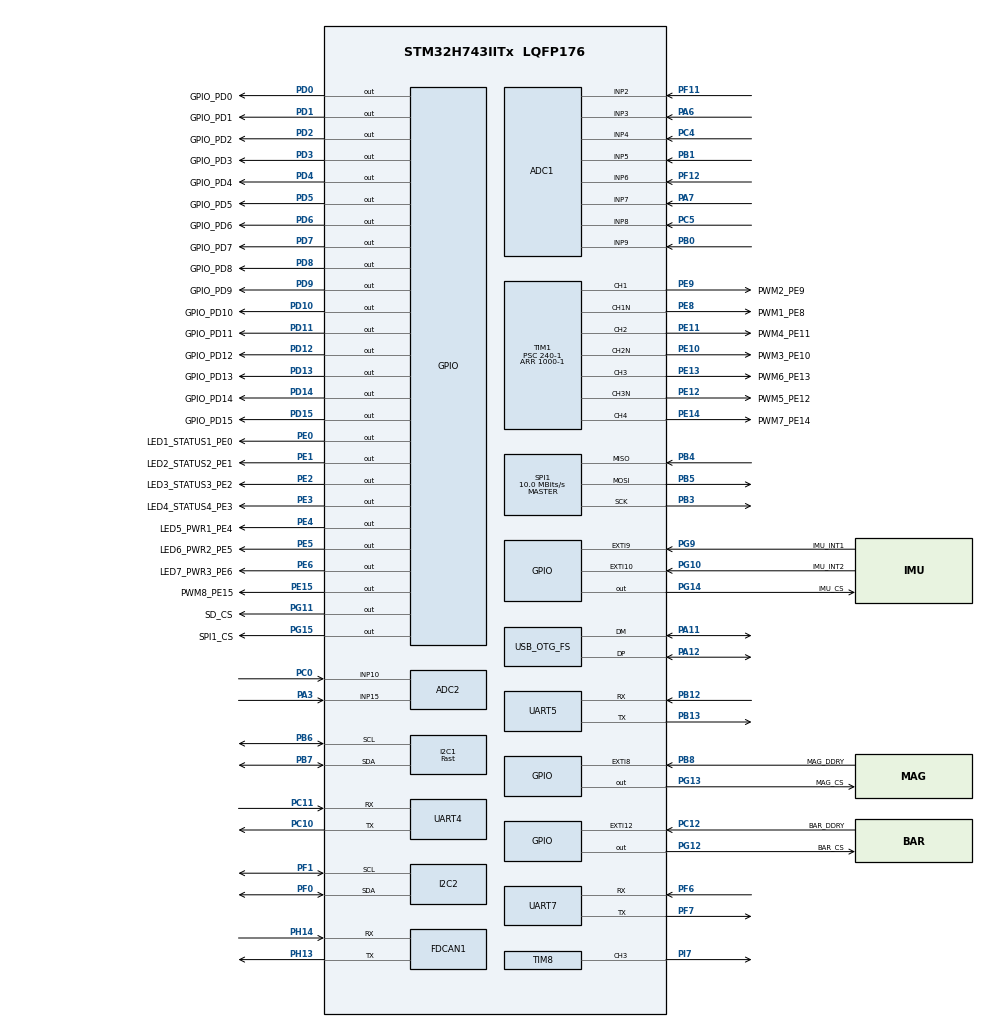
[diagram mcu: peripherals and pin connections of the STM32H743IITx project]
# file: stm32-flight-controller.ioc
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ADC1.Channel-1\#ChannelRegularConversion=ADC_CHANNEL_6
ADC1.ClockPrescaler=ADC_CLOCK_ASYNC_DIV2
ADC1.NbrOfConversionFlag=1
ADC1.OffsetNumber-1\#ChannelRegularConversion=ADC_OFFSET_NONE
ADC1.OffsetSignedSaturation-1\#ChannelRegularConversion=DISABLE
ADC1.Rank-1\#ChannelRegularConversion=1
ADC1.SamplingTime-1\#ChannelRegularConversion=ADC_SAMPLETIME_1CYCLE_5
ADC1.master=1
ADC2.Channel-0\#ChannelRegularConversion=ADC_CHANNEL_10
ADC2.ClockPrescaler=ADC_CLOCK_ASYNC_DIV2
ADC2.NbrOfConversionFlag=1
ADC2.OffsetNumber-0\#ChannelRegularConversion=ADC_OFFSET_NONE
ADC2.OffsetSignedSaturation-0\#ChannelRegularConversion=DISABLE
ADC2.Rank-0\#ChannelRegularConversion=1
ADC2.SamplingTime-0\#ChannelRegularConversion=ADC_SAMPLETIME_1CYCLE_5
CORTEX_M7.default_mode_Activation=1
FDCAN1.CalculateBaudRateNominal=1499999
FDCAN1.CalculateTimeBitNominal=666
FDCAN1.CalculateTimeQuantumNominal=133.33333333333334
FREERTOS.Mutexes01=spi1Mutex,Dynamic,NULL,Available;i2c1Mutex,Dynamic,NULL,Available;i2c2Mutex,Dynamic,NULL,Available;usbMutex,Dynamic,NULL,Available;fdcanMutex,Dynamic,NULL,Available
FREERTOS.Tasks01=defaultTask,24,512,StartDefaultTask,Default,NULL,Dynamic,NULL,NULL;statusLedTask,8,128,StartStatusLedTask,As external,NULL,Dynamic,NULL,NULL;gpsTask,24,512,StartGpsTask,As external,NULL,Dynamic,NULL,NULL;imuTask,24,512,StartImuTask,As external,NULL,Dynamic,NULL,NULL;magTask,24,512,StartMagTask,As external,NULL,Dynamic,NULL,NULL;barTask,24,512,StartBarTask,As external,NULL,Dynamic,NULL,NULL;fusionTask,40,1024,StartFusionTask,As external,NULL,Dynamic,NULL,NULL;controlTask,48,1024,StartControlTask,As external,NULL,Dynamic,NULL,NULL;tofTask,24,512,StartTofTask,As external,NULL,Dynamic,NULL,NULL
FREERTOS.configENABLE_FPU=1
FREERTOS.configTOTAL_HEAP_SIZE=51200
FREERTOS.configUSE_NEWLIB_REENTRANT=0
I2C1.I2C_Speed_Mode=I2C_Fast
I2C1.Timing=0x00B03FDB
I2C2.Timing=0x307075B1
Mcu.Family=STM32H7
Mcu.Name=STM32H743IITx
Mcu.Package=LQFP176
NVIC.OTG_FS_IRQn=true\:5\:0\:false\:false\:true\:true\:false\:true\:true
NVIC.PriorityGroup=NVIC_PRIORITYGROUP_4
NVIC.TIM2_IRQn=true\:15\:0\:false\:false\:true\:false\:false\:true\:true
NVIC.TimeBase=TIM2_IRQn
NVIC.TimeBaseIP=TIM2
NVIC.UART4_IRQn=true\:5\:0\:false\:false\:true\:true\:true\:true\:true
PA11.Mode=Device_Only
PA11.Signal=USB_OTG_FS_DM
PA12.Mode=Device_Only
PA12.Signal=USB_OTG_FS_DP
PA13\ (JTMS/SWDIO).Mode=Serial_Wire
PA13\ (JTMS/SWDIO).Signal=DEBUG_JTMS-SWDIO
PA14\ (JTCK/SWCLK).Mode=Serial_Wire
PA14\ (JTCK/SWCLK).Signal=DEBUG_JTCK-SWCLK
PA3.Signal=ADCx_INP15
PA6.Signal=ADCx_INP3
PA7.Signal=ADCx_INP7
PB0.Signal=ADCx_INP9
PB1.Signal=ADCx_INP5
PB12.Mode=Asynchronous
PB12.Signal=UART5_RX
PB13.Mode=Asynchronous
PB13.Signal=UART5_TX
PB3\ (JTDO/TRACESWO).GPIO_PuPd=GPIO_NOPULL
PB3\ (JTDO/TRACESWO).GPIO_Speed=GPIO_SPEED_FREQ_VERY_HIGH
PB3\ (JTDO/TRACESWO).Mode=Full_Duplex_Master
PB3\ (JTDO/TRACESWO).Signal=SPI1_SCK
PB4\ (NJTRST).GPIO_PuPd=GPIO_NOPULL
PB4\ (NJTRST).GPIO_Speed=GPIO_SPEED_FREQ_VERY_HIGH
PB4\ (NJTRST).Mode=Full_Duplex_Master
PB4\ (NJTRST).Signal=SPI1_MISO
PB5.GPIO_PuPd=GPIO_NOPULL
PB5.GPIO_Speed=GPIO_SPEED_FREQ_VERY_HIGH
PB5.Mode=Full_Duplex_Master
PB5.Signal=SPI1_MOSI
PB6.GPIO_Speed=GPIO_SPEED_FREQ_VERY_HIGH
PB6.Mode=I2C
PB6.Signal=I2C1_SCL
PB7.GPIO_Speed=GPIO_SPEED_FREQ_VERY_HIGH
PB7.Mode=I2C
PB7.Signal=I2C1_SDA
PB8.GPIO_Label=MAG_DDRY
PB8.Signal=GPXTI8
PC0.Signal=ADCx_INP10
PC10.Mode=Asynchronous
PC10.Signal=UART4_TX
PC11.Mode=Asynchronous
PC11.Signal=UART4_RX
PC12.GPIO_Label=BAR_DDRY
PC12.Signal=GPXTI12
PC4.Signal=ADCx_INP4
PC5.Signal=ADCx_INP8
PD0.GPIO_Label=GPIO_PD0
PD0.Signal=GPIO_Output
PD1.GPIO_Label=GPIO_PD1
PD1.Signal=GPIO_Output
PD10.GPIO_Label=GPIO_PD10
PD10.Signal=GPIO_Output
PD11.GPIO_Label=GPIO_PD11
PD11.Signal=GPIO_Output
PD12.GPIO_Label=GPIO_PD12
PD12.Signal=GPIO_Output
PD13.GPIO_Label=GPIO_PD13
PD13.Signal=GPIO_Output
PD14.GPIO_Label=GPIO_PD14
PD14.Signal=GPIO_Output
PD15.GPIO_Label=GPIO_PD15
PD15.Signal=GPIO_Output
PD2.GPIO_Label=GPIO_PD2
PD2.Signal=GPIO_Output
PD3.GPIO_Label=GPIO_PD3
PD3.Signal=GPIO_Output
PD4.GPIO_Label=GPIO_PD4
PD4.Signal=GPIO_Output
PD5.GPIO_Label=GPIO_PD5
PD5.Signal=GPIO_Output
PD6.GPIO_Label=GPIO_PD6
PD6.Signal=GPIO_Output
PD7.GPIO_Label=GPIO_PD7
PD7.Signal=GPIO_Output
PD8.GPIO_Label=GPIO_PD8
PD8.Signal=GPIO_Output
PD9.GPIO_Label=GPIO_PD9
PD9.Signal=GPIO_Output
PE0.GPIO_Label=LED1_STATUS1_PE0
PE0.Signal=GPIO_Output
PE1.GPIO_Label=LED2_STATUS2_PE1
PE1.Signal=GPIO_Output
PE10.GPIO_Label=PWM3_PE10
PE10.Mode=PWM Generation2 CH2 CH2N
PE10.Signal=TIM1_CH2N
PE11.GPIO_Label=PWM4_PE11
PE11.Signal=S_TIM1_CH2
PE12.GPIO_Label=PWM5_PE12
PE12.Mode=PWM Generation3 CH3 CH3N
PE12.Signal=TIM1_CH3N
PE13.GPIO_Label=PWM6_PE13
PE13.Signal=S_TIM1_CH3
PE14.GPIO_Label=PWM7_PE14
PE14.Signal=S_TIM1_CH4
PE15.GPIO_Label=PWM8_PE15
PE15.Signal=GPIO_Output
PE2.GPIO_Label=LED3_STATUS3_PE2
PE2.Signal=GPIO_Output
PE3.GPIO_Label=LED4_STATUS4_PE3
PE3.Signal=GPIO_Output
PE4.GPIO_Label=LED5_PWR1_PE4
PE4.Signal=GPIO_Output
PE5.GPIO_Label=LED6_PWR2_PE5
PE5.Signal=GPIO_Output
PE6.GPIO_Label=LED7_PWR3_PE6
PE6.Signal=GPIO_Output
PE8.GPIO_Label=PWM1_PE8
PE8.Mode=PWM Generation1 CH1 CH1N
PE8.Signal=TIM1_CH1N
PE9.GPIO_Label=PWM2_PE9
PE9.Signal=S_TIM1_CH1
PF0.Mode=I2C
PF0.Signal=I2C2_SDA
PF1.Mode=I2C
PF1.Signal=I2C2_SCL
PF11.Mode=IN2-Single-Ended
PF11.Signal=ADC1_INP2
PF12.Mode=IN6-Single-Ended
PF12.Signal=ADC1_INP6
PF6.Mode=Asynchronous
PF6.Signal=UART7_RX
PF7.Mode=Asynchronous
PF7.Signal=UART7_TX
PG10.GPIO_Label=IMU_INT2
PG10.Signal=GPXTI10
PG11.GPIO_Label=SD_CS
PG11.Signal=GPIO_Output
PG12.GPIO_Label=BAR_CS
PG12.Signal=GPIO_Output
PG13.GPIO_Label=MAG_CS
PG13.Signal=GPIO_Output
PG14.GPIO_Label=IMU_CS
PG14.Signal=GPIO_Output
PG15.GPIO_Label=SPI1_CS
PG15.Signal=GPIO_Output
PG9.GPIO_Label=IMU_INT1
PG9.Signal=GPXTI9
PH0-OSC_IN\ (PH0).Mode=HSE-External-Oscillator
PH0-OSC_IN\ (PH0).Signal=RCC_OSC_IN
PH1-OSC_OUT\ (PH1).Mode=HSE-External-Oscillator
PH1-OSC_OUT\ (PH1).Signal=RCC_OSC_OUT
PH13.Mode=FDCAN_Activate
PH13.Signal=FDCAN1_TX
PH14.Mode=FDCAN_Activate
PH14.Signal=FDCAN1_RX
PI7.Signal=S_TIM8_CH3
ProjectManager.HeapSize=0x200
ProjectManager.StackSize=0x400
ProjectManager.TargetToolchain=Makefile
RCC.ADCFreq_Value=80000000
RCC.APB1Freq_Value=120000000
RCC.APB2Freq_Value=120000000
RCC.APB3Freq_Value=120000000
RCC.APB4Freq_Value=120000000
RCC.CortexFreq_Value=480000000
RCC.D1PPRE=RCC_APB3_DIV2
RCC.D2PPRE1=RCC_APB1_DIV2
RCC.D2PPRE2=RCC_APB2_DIV2
RCC.D3PPRE=RCC_APB4_DIV2
RCC.DIVM1=1
RCC.DIVM2=1
RCC.DIVM3=8
RCC.DIVN1=60
RCC.DIVN2=10
RCC.DIVQ1=8
RCC.HCLKFreq_Value=240000000
RCC.HPRE=RCC_HCLK_DIV2
RCC.HSE_VALUE=16000000
RCC.LockedElements=D1CPREOutput,APB2Output,APB1Output,SPI123output,ADCoutput,USART234578output
RCC.PLL2FRACN=0
RCC.PLL3FRACN=0
RCC.PLL3_VCI_Range-AdvancedSettings=RCC_PLL3VCIRANGE_3
RCC.PLLFRACN=0
RCC.PLLSourceVirtual=RCC_PLLSOURCE_HSE
RCC.SPI123CLockSelection=RCC_SPI123CLKSOURCE_PLL2
RCC.SYSCLKFreq_VALUE=480000000
RCC.SYSCLKSource=RCC_SYSCLKSOURCE_PLLCLK
RCC.USART234578CLockSelection=RCC_USART234578CLKSOURCE_PLL2
RCC.USBCLockSelection=RCC_USBCLKSOURCE_HSI48
RCC.USBFreq_Value=48000000
SH.ADCx_INP10.0=ADC2_INP10,IN10-Single-Ended
SH.ADCx_INP15.0=ADC2_INP15,IN15-Single-Ended
SH.ADCx_INP3.0=ADC1_INP3,IN3-Single-Ended
SH.ADCx_INP4.0=ADC1_INP4,IN4-Single-Ended
SH.ADCx_INP5.0=ADC1_INP5,IN5-Single-Ended
SH.ADCx_INP7.0=ADC1_INP7,IN7-Single-Ended
SH.ADCx_INP8.0=ADC1_INP8,IN8-Single-Ended
SH.ADCx_INP9.0=ADC1_INP9,IN9-Single-Ended
SH.S_TIM1_CH1.0=TIM1_CH1,PWM Generation1 CH1 CH1N
SH.S_TIM1_CH2.0=TIM1_CH2,PWM Generation2 CH2 CH2N
SH.S_TIM1_CH3.0=TIM1_CH3,PWM Generation3 CH3 CH3N
SH.S_TIM1_CH4.0=TIM1_CH4,PWM Generation4 CH4
SH.S_TIM8_CH3.0=TIM8_CH3,PWM Generation3 CH3
SPI1.BaudRatePrescaler=SPI_BAUDRATEPRESCALER_8
SPI1.CalculateBaudRate=10.0 MBits/s
SPI1.DataSize=SPI_DATASIZE_8BIT
SPI1.Direction=SPI_DIRECTION_2LINES
SPI1.Mode=SPI_MODE_MASTER
SPI1.VirtualType=VM_MASTER
STMicroelectronics.X-CUBE-MEMS1.10.0.0.BSP.number=3
STMicroelectronics.X-CUBE-MEMS1.10.0.0.BoardOoPartJjAccGyrJjLSM6DSO=SPI
STMicroelectronics.X-CUBE-MEMS1.10.0.0.BoardOoPartJjMagJjLIS3MDL=SPI
STMicroelectronics.X-CUBE-MEMS1.10.0.0.BoardOoPartJjPressTempJjLPS22HH=SPI
STMicroelectronics.X-CUBE-MEMS1.10.0.00.BSP.STBoard=false
STMicroelectronics.X-CUBE-MEMS1.10.0.00.BSP.api=Unknown
STMicroelectronics.X-CUBE-MEMS1.10.0.00.BSP.condition=SEMBoardOoPartJjMagJjLIS3MDLJjSPI
STMicroelectronics.X-CUBE-MEMS1.10.0.00.BSP.instance=PG13
STMicroelectronics.X-CUBE-MEMS1.10.0.00.BSP.ip=GPIO
STMicroelectronics.X-CUBE-MEMS1.10.0.00.BSP.mode=Output
STMicroelectronics.X-CUBE-MEMS1.10.0.00.BSP.name=LIS3MDL_CS
STMicroelectronics.X-CUBE-MEMS1.10.0.00.BSP.solution=PG13
STMicroelectronics.X-CUBE-MEMS1.10.0.01.BSP.STBoard=false
STMicroelectronics.X-CUBE-MEMS1.10.0.01.BSP.api=Unknown
STMicroelectronics.X-CUBE-MEMS1.10.0.01.BSP.condition=SEMBoardOoPartJjPressTempJjLPS22HHJjSPI
STMicroelectronics.X-CUBE-MEMS1.10.0.01.BSP.instance=PG12
STMicroelectronics.X-CUBE-MEMS1.10.0.01.BSP.ip=GPIO
STMicroelectronics.X-CUBE-MEMS1.10.0.01.BSP.mode=Output
STMicroelectronics.X-CUBE-MEMS1.10.0.01.BSP.name=LPS22HH_CS
STMicroelectronics.X-CUBE-MEMS1.10.0.01.BSP.solution=PG12
STMicroelectronics.X-CUBE-MEMS1.10.0.02.BSP.STBoard=false
STMicroelectronics.X-CUBE-MEMS1.10.0.02.BSP.api=Unknown
STMicroelectronics.X-CUBE-MEMS1.10.0.02.BSP.condition=SEMBoardOoPartJjAccGyrJjLSM6DSOJjSPI
STMicroelectronics.X-CUBE-MEMS1.10.0.02.BSP.instance=PG14
STMicroelectronics.X-CUBE-MEMS1.10.0.02.BSP.ip=GPIO
STMicroelectronics.X-CUBE-MEMS1.10.0.02.BSP.mode=Output
STMicroelectronics.X-CUBE-MEMS1.10.0.02.BSP.name=LSM6DSO_CS
STMicroelectronics.X-CUBE-MEMS1.10.0.02.BSP.solution=PG14
TIM1.AutoReloadPreload=TIM_AUTORELOAD_PRELOAD_ENABLE
TIM1.Channel-PWM\ Generation1\ CH1\ CH1N=TIM_CHANNEL_1
TIM1.Channel-PWM\ Generation2\ CH2\ CH2N=TIM_CHANNEL_2
TIM1.Channel-PWM\ Generation3\ CH3\ CH3N=TIM_CHANNEL_3
TIM1.Channel-PWM\ Generation4\ CH4=TIM_CHANNEL_4
TIM1.Period=1000-1
TIM1.Prescaler=240-1
TIM8.AutoReloadPreload=TIM_AUTORELOAD_PRELOAD_ENABLE
TIM8.Channel-PWM\ Generation3\ CH3=TIM_CHANNEL_3
TIM8.Period=1000-1
TIM8.Prescaler=120-1
USB_DEVICE.CLASS_NAME_FS=CDC
USB_DEVICE.VirtualMode-CDC_FS=Cdc
USB_DEVICE.VirtualModeFS=Cdc_FS
USB_OTG_FS.VirtualMode=Device_Only
USB_OTG_FS.lpm_enable=DISABLE
VP_FREERTOS_VS_CMSIS_V2.Mode=CMSIS_V2
VP_MEMORYMAP_VS_MEMORYMAP.Mode=CurAppReg
VP_STMicroelectronics.X-CUBE-MEMS1_VS_BoardOoPartJjAccGyr_5.5.0_10.0.0.Mode=BoardOoPartJjAccGyr
VP_STMicroelectronics.X-CUBE-MEMS1_VS_BoardOoPartJjMag_5.4.0_10.0.0.Mode=BoardOoPartJjMag
VP_STMicroelectronics.X-CUBE-MEMS1_VS_BoardOoPartJjPressTemp_5.6.0_10.0.0.Mode=BoardOoPartJjPressTemp
VP_SYS_VS_tim2.Mode=TIM2
VP_TIM1_VS_ClockSourceINT.Mode=Internal
VP_TIM8_VS_ClockSourceINT.Mode=Internal
VP_USB_DEVICE_VS_USB_DEVICE_CDC_FS.Mode=CDC_FS
board=custom

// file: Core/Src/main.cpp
/* USER CODE BEGIN Header */
/**
 ******************************************************************************
 * @file           : main.c
 * @brief          : Main program body
 ******************************************************************************
 * @attention
 *
 * Copyright (c) 2024 STMicroelectronics.
 * All rights reserved.
 *
 * This software is licensed under terms that can be found in the LICENSE file
 * in the root directory of this software component.
 * If no LICENSE file comes with this software, it is provided AS-IS.
 *
 ******************************************************************************
 */
/* USER CODE END Header */
#include "main.h"
#include "cmsis_os.h"
#include "adc.h"
#include "fdcan.h"
#include "i2c.h"
#include "memorymap.h"
#include "spi.h"
#include "tim.h"
#include "usart.h"
#include "usb_device.h"
#include "gpio.h"

/* USER CODE BEGIN Includes */
#include <stdio.h>
#include "usbd_cdc_if.h"

/* USER CODE END Includes */

void SystemClock_Config(void);
void PeriphCommonClock_Config(void);
static void MPU_Config(void);

/* USER CODE BEGIN 0 */

extern osMutexId_t usbMutexHandle;

int _write(int file, char *ptr, int length)
{
	(void)file;

	// Wait for the USB mutex
	osMutexAcquire(usbMutexHandle, osWaitForever);

	// Transmit the data
	CDC_Transmit_FS((uint8_t *)ptr, length);

	// Release the USB mutex
	osMutexRelease(usbMutexHandle);

	return length;
}

/* USER CODE END 0 */

int main(void)
{

	/* MPU Configuration--------------------------------------------------------*/
	MPU_Config();

	/* MCU Configuration--------------------------------------------------------*/

	/* Reset of all peripherals, Initializes the Flash interface and the Systick. */
	HAL_Init();

	/* Configure the system clock */
	SystemClock_Config();

	/* Configure the peripherals common clocks */
	PeriphCommonClock_Config();

	/* Initialize all configured peripherals */
	MX_GPIO_Init();
	MX_FDCAN1_Init();
	MX_I2C1_Init();
	MX_UART4_Init();
	MX_ADC1_Init();
	MX_ADC2_Init();
	MX_I2C2_Init();
	MX_UART7_Init();
	MX_TIM1_Init();
	MX_TIM8_Init();
	MX_UART5_Init();
	MX_SPI1_Init();
	/* USER CODE BEGIN 2 */
	MX_USB_DEVICE_Init();

	// Set all CS pins high
	HAL_GPIO_WritePin(SD_CS_GPIO_Port, SD_CS_Pin, GPIO_PIN_SET);
	HAL_GPIO_WritePin(BAR_CS_GPIO_Port, BAR_CS_Pin, GPIO_PIN_SET);
	HAL_GPIO_WritePin(MAG_CS_GPIO_Port, MAG_CS_Pin, GPIO_PIN_SET);
	HAL_GPIO_WritePin(IMU_CS_GPIO_Port, IMU_CS_Pin, GPIO_PIN_SET);
	HAL_GPIO_WritePin(SPI1_CS_GPIO_Port, SPI1_CS_Pin, GPIO_PIN_SET);

	/* USER CODE END 2 */

	/* Init scheduler */
	osKernelInitialize();

	/* Call init function for freertos objects (in cmsis_os2.c) */
	MX_FREERTOS_Init();

	/* Start scheduler */
	osKernelStart();

	/* We should never get here as control is now taken by the scheduler */

	/* Infinite loop */
	while (1)
	{

	}
}

void SystemClock_Config(void)
{
	RCC_OscInitTypeDef RCC_OscInitStruct = {0};
	RCC_ClkInitTypeDef RCC_ClkInitStruct = {0};

	/** Supply configuration update enable
	 */
	HAL_PWREx_ConfigSupply(PWR_LDO_SUPPLY);

	/** Configure the main internal regulator output voltage
	 */
	__HAL_PWR_VOLTAGESCALING_CONFIG(PWR_REGULATOR_VOLTAGE_SCALE1);

	while (!__HAL_PWR_GET_FLAG(PWR_FLAG_VOSRDY))
	{
	}

	__HAL_RCC_SYSCFG_CLK_ENABLE();
	__HAL_PWR_VOLTAGESCALING_CONFIG(PWR_REGULATOR_VOLTAGE_SCALE0);

	while (!__HAL_PWR_GET_FLAG(PWR_FLAG_VOSRDY))
	{
	}

	/** Initializes the RCC Oscillators according to the specified parameters
	 * in the RCC_OscInitTypeDef structure.
	 */
	RCC_OscInitStruct.OscillatorType = RCC_OSCILLATORTYPE_HSI48 | RCC_OSCILLATORTYPE_HSE;
	RCC_OscInitStruct.HSEState = RCC_HSE_ON;
	RCC_OscInitStruct.HSI48State = RCC_HSI48_ON;
	RCC_OscInitStruct.PLL.PLLState = RCC_PLL_ON;
	RCC_OscInitStruct.PLL.PLLSource = RCC_PLLSOURCE_HSE;
	RCC_OscInitStruct.PLL.PLLM = 1;
	RCC_OscInitStruct.PLL.PLLN = 60;
	RCC_OscInitStruct.PLL.PLLP = 2;
	RCC_OscInitStruct.PLL.PLLQ = 8;
	RCC_OscInitStruct.PLL.PLLR = 2;
	RCC_OscInitStruct.PLL.PLLRGE = RCC_PLL1VCIRANGE_3;
	RCC_OscInitStruct.PLL.PLLVCOSEL = RCC_PLL1VCOWIDE;
	RCC_OscInitStruct.PLL.PLLFRACN = 0;
	if (HAL_RCC_OscConfig(&RCC_OscInitStruct) != HAL_OK)
	{
		Error_Handler();
	}

	/** Initializes the CPU, AHB and APB buses clocks
	 */
	RCC_ClkInitStruct.ClockType = RCC_CLOCKTYPE_HCLK | RCC_CLOCKTYPE_SYSCLK | RCC_CLOCKTYPE_PCLK1 | RCC_CLOCKTYPE_PCLK2 | RCC_CLOCKTYPE_D3PCLK1 | RCC_CLOCKTYPE_D1PCLK1;
	RCC_ClkInitStruct.SYSCLKSource = RCC_SYSCLKSOURCE_PLLCLK;
	RCC_ClkInitStruct.SYSCLKDivider = RCC_SYSCLK_DIV1;
	RCC_ClkInitStruct.AHBCLKDivider = RCC_HCLK_DIV2;
	RCC_ClkInitStruct.APB3CLKDivider = RCC_APB3_DIV2;
	RCC_ClkInitStruct.APB1CLKDivider = RCC_APB1_DIV2;
	RCC_ClkInitStruct.APB2CLKDivider = RCC_APB2_DIV2;
	RCC_ClkInitStruct.APB4CLKDivider = RCC_APB4_DIV2;

	if (HAL_RCC_ClockConfig(&RCC_ClkInitStruct, FLASH_LATENCY_4) != HAL_OK)
	{
		Error_Handler();
	}
}

void PeriphCommonClock_Config(void)
{
	RCC_PeriphCLKInitTypeDef PeriphClkInitStruct = {0};

	/** Initializes the peripherals clock
	 */
	PeriphClkInitStruct.PeriphClockSelection = RCC_PERIPHCLK_ADC | RCC_PERIPHCLK_SPI1 | RCC_PERIPHCLK_UART5 | RCC_PERIPHCLK_UART7 | RCC_PERIPHCLK_UART4;
	PeriphClkInitStruct.PLL2.PLL2M = 1;
	PeriphClkInitStruct.PLL2.PLL2N = 10;
	PeriphClkInitStruct.PLL2.PLL2P = 2;
	PeriphClkInitStruct.PLL2.PLL2Q = 2;
	PeriphClkInitStruct.PLL2.PLL2R = 2;
	PeriphClkInitStruct.PLL2.PLL2RGE = RCC_PLL2VCIRANGE_3;
	PeriphClkInitStruct.PLL2.PLL2VCOSEL = RCC_PLL2VCOMEDIUM;
	PeriphClkInitStruct.PLL2.PLL2FRACN = 0;
	PeriphClkInitStruct.Spi123ClockSelection = RCC_SPI123CLKSOURCE_PLL2;
	PeriphClkInitStruct.Usart234578ClockSelection = RCC_USART234578CLKSOURCE_PLL2;
	PeriphClkInitStruct.AdcClockSelection = RCC_ADCCLKSOURCE_PLL2;
	if (HAL_RCCEx_PeriphCLKConfig(&PeriphClkInitStruct) != HAL_OK)
	{
		Error_Handler();
	}
}

/* MPU Configuration */

void MPU_Config(void)
{
	MPU_Region_InitTypeDef MPU_InitStruct = {0};

	/* Disables the MPU */
	HAL_MPU_Disable();

	/** Initializes and configures the Region and the memory to be protected
	 */
	MPU_InitStruct.Enable = MPU_REGION_ENABLE;
	MPU_InitStruct.Number = MPU_REGION_NUMBER0;
	MPU_InitStruct.BaseAddress = 0x0;
	MPU_InitStruct.Size = MPU_REGION_SIZE_4GB;
	MPU_InitStruct.SubRegionDisable = 0x87;
	MPU_InitStruct.TypeExtField = MPU_TEX_LEVEL0;
	MPU_InitStruct.AccessPermission = MPU_REGION_NO_ACCESS;
	MPU_InitStruct.DisableExec = MPU_INSTRUCTION_ACCESS_DISABLE;
	MPU_InitStruct.IsShareable = MPU_ACCESS_SHAREABLE;
	MPU_InitStruct.IsCacheable = MPU_ACCESS_NOT_CACHEABLE;
	MPU_InitStruct.IsBufferable = MPU_ACCESS_NOT_BUFFERABLE;

	HAL_MPU_ConfigRegion(&MPU_InitStruct);
	/* Enables the MPU */
	HAL_MPU_Enable(MPU_PRIVILEGED_DEFAULT);
}

void HAL_TIM_PeriodElapsedCallback(TIM_HandleTypeDef *htim)
{
	if (htim->Instance == TIM2)
	{
		HAL_IncTick();
	}
}

void Error_Handler(void)
{
	__disable_irq();
	while (1)
	{
	}
}
